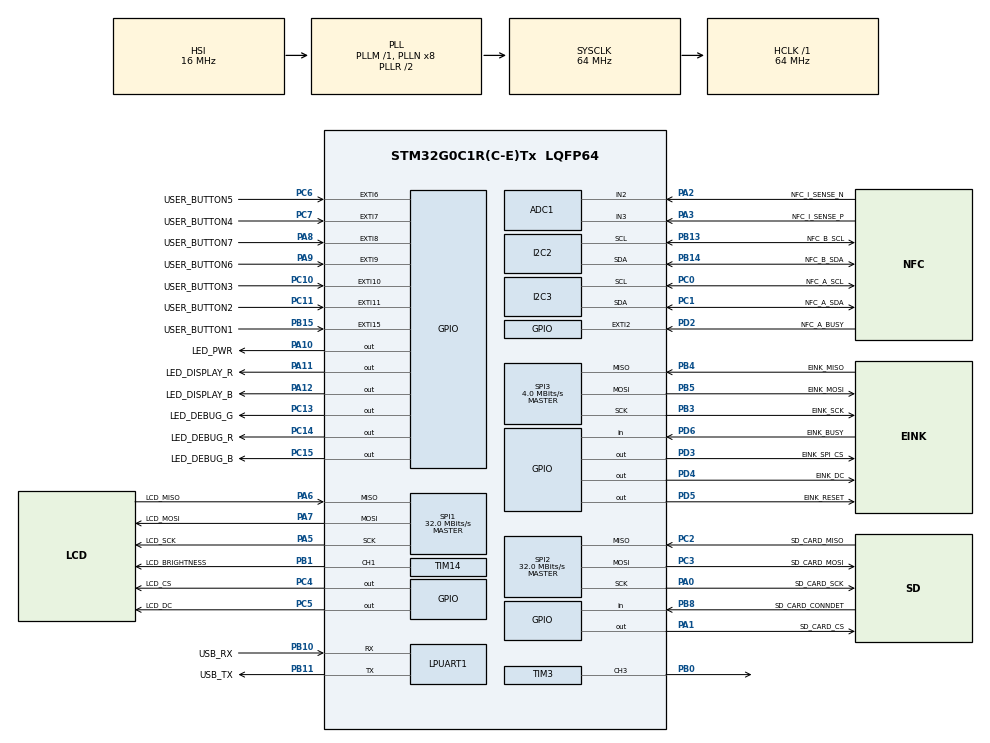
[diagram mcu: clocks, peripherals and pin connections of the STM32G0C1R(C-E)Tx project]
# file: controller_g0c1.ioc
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ADC1.Channel-0\#ChannelRegularConversion=ADC_CHANNEL_2
ADC1.NbrOfConversionFlag=1
ADC1.Rank-0\#ChannelRegularConversion=1
ADC1.SamplingTime-0\#ChannelRegularConversion=ADC_SAMPLINGTIME_COMMON_1
ADC1.SelectedChannel=ADC_CHANNEL_2|ADC_CHANNEL_3
ADC1.master=1
FREERTOS.Tasks01=defaultTask,24,128,StartDefaultTask,Default,NULL,Dynamic,NULL,NULL
FREERTOS.configUSE_NEWLIB_REENTRANT=1
I2C2.Timing=0x10B17DB5
I2C3.Speed=100
I2C3.Timing=0x10B17DB5
Mcu.Family=STM32G0
Mcu.Name=STM32G0C1R(C-E)Tx
Mcu.Package=LQFP64
NVIC.EXTI2_3_IRQn=true\:3\:0\:false\:false\:true\:true\:true\:true\:true
NVIC.EXTI4_15_IRQn=true\:3\:0\:false\:false\:true\:true\:true\:true\:true
NVIC.I2C2_3_IRQn=true\:3\:0\:false\:false\:true\:true\:true\:true\:true
NVIC.TIM1_BRK_UP_TRG_COM_IRQn=true\:3\:0\:false\:false\:true\:false\:false\:true\:true
NVIC.TimeBase=TIM1_BRK_UP_TRG_COM_IRQn
NVIC.TimeBaseIP=TIM1
PA0.GPIO_Label=SD_CARD_SCK
PA0.Mode=Full_Duplex_Master
PA0.Signal=SPI2_SCK
PA1.GPIO_Label=SD_CARD_CS
PA1.Signal=GPIO_Output
PA10.GPIO_Label=LED_PWR
PA10.Signal=GPIO_Output
PA11\ [PA9].GPIO_Label=LED_DISPLAY_R
PA11\ [PA9].Signal=GPIO_Output
PA12\ [PA10].GPIO_Label=LED_DISPLAY_B
PA12\ [PA10].Signal=GPIO_Output
PA2.GPIO_Label=NFC_I_SENSE_N
PA2.Mode=IN2
PA2.Signal=ADC1_IN2
PA3.GPIO_Label=NFC_I_SENSE_P
PA3.Mode=IN3
PA3.Signal=ADC1_IN3
PA5.GPIO_Label=LCD_SCK
PA5.Mode=Full_Duplex_Master
PA5.Signal=SPI1_SCK
PA6.GPIO_Label=LCD_MISO
PA6.Mode=Full_Duplex_Master
PA6.Signal=SPI1_MISO
PA7.GPIO_Label=LCD_MOSI
PA7.Mode=Full_Duplex_Master
PA7.Signal=SPI1_MOSI
PA8.GPIO_Label=USER_BUTTON7
PA8.GPIO_ModeDefaultEXTI=GPIO_MODE_IT_RISING_FALLING
PA8.Signal=GPXTI8
PA9.GPIO_Label=USER_BUTTON6
PA9.GPIO_ModeDefaultEXTI=GPIO_MODE_IT_RISING_FALLING
PA9.Signal=GPXTI9
PB0.Signal=S_TIM3_CH3
PB1.GPIO_Label=LCD_BRIGHTNESS
PB1.Signal=S_TIM14_CH1
PB10.GPIO_Label=USB_RX
PB10.Mode=Asynchronous
PB10.Signal=LPUART1_RX
PB11.GPIO_Label=USB_TX
PB11.Mode=Asynchronous
PB11.Signal=LPUART1_TX
PB13.GPIO_Label=NFC_B_SCL
PB13.Mode=I2C
PB13.Signal=I2C2_SCL
PB14.GPIO_Label=NFC_B_SDA
PB14.Mode=I2C
PB14.Signal=I2C2_SDA
PB15.GPIO_Label=USER_BUTTON1
PB15.GPIO_ModeDefaultEXTI=GPIO_MODE_IT_RISING_FALLING
PB15.Signal=GPXTI15
PB3.GPIO_Label=EINK_SCK
PB3.Mode=Full_Duplex_Master
PB3.Signal=SPI3_SCK
PB4.GPIO_Label=EINK_MISO
PB4.Mode=Full_Duplex_Master
PB4.Signal=SPI3_MISO
PB5.GPIO_Label=EINK_MOSI
PB5.Mode=Full_Duplex_Master
PB5.Signal=SPI3_MOSI
PB8.GPIO_Label=SD_CARD_CONNDET
PB8.Signal=GPIO_Input
PC0.GPIO_Label=NFC_A_SCL
PC0.Mode=I2C
PC0.Signal=I2C3_SCL
PC1.GPIO_Label=NFC_A_SDA
PC1.Mode=I2C
PC1.Signal=I2C3_SDA
PC10.GPIO_Label=USER_BUTTON3
PC10.GPIO_ModeDefaultEXTI=GPIO_MODE_IT_RISING_FALLING
PC10.Signal=GPXTI10
PC11.GPIO_Label=USER_BUTTON2
PC11.GPIO_ModeDefaultEXTI=GPIO_MODE_IT_RISING_FALLING
PC11.Signal=GPXTI11
PC13.GPIO_Label=LED_DEBUG_G
PC13.Signal=GPIO_Output
PC14-OSC32_IN\ (PC14).GPIO_Label=LED_DEBUG_R
PC14-OSC32_IN\ (PC14).Signal=GPIO_Output
PC15-OSC32_OUT\ (PC15).GPIO_Label=LED_DEBUG_B
PC15-OSC32_OUT\ (PC15).Signal=GPIO_Output
PC2.GPIO_Label=SD_CARD_MISO
PC2.Mode=Full_Duplex_Master
PC2.Signal=SPI2_MISO
PC3.GPIO_Label=SD_CARD_MOSI
PC3.Mode=Full_Duplex_Master
PC3.Signal=SPI2_MOSI
PC4.GPIO_Label=LCD_CS
PC4.Signal=GPIO_Output
PC5.GPIO_Label=LCD_DC
PC5.Signal=GPIO_Output
PC6.GPIO_Label=USER_BUTTON5
PC6.GPIO_ModeDefaultEXTI=GPIO_MODE_IT_RISING_FALLING
PC6.Signal=GPXTI6
PC7.GPIO_Label=USER_BUTTON4
PC7.GPIO_ModeDefaultEXTI=GPIO_MODE_IT_RISING_FALLING
PC7.Signal=GPXTI7
PD2.GPIO_Label=NFC_A_BUSY
PD2.Signal=GPXTI2
PD3.GPIO_Label=EINK_SPI_CS
PD3.Signal=GPIO_Output
PD4.GPIO_Label=EINK_DC
PD4.Signal=GPIO_Output
PD5.GPIO_Label=EINK_RESET
PD5.Signal=GPIO_Output
PD6.GPIO_Label=EINK_BUSY
PD6.Signal=GPIO_Input
ProjectManager.HeapSize=0x200
ProjectManager.StackSize=0x400
ProjectManager.TargetToolchain=STM32CubeIDE
RCC.ADCFreq_Value=64000000
RCC.AHBFreq_Value=64000000
RCC.CortexFreq_Value=64000000
RCC.EXTERNAL_CLOCK_VALUE=48000
RCC.HCLKFreq_Value=64000000
RCC.HSE_VALUE=8000000
RCC.HSI48_VALUE=48000000
RCC.HSI_VALUE=16000000
RCC.LSE_VALUE=32768
RCC.SYSCLKFreq_VALUE=64000000
RCC.SYSCLKSource=RCC_SYSCLKSOURCE_PLLCLK
RCC.USBFreq_Value=48000000
RCC.VCOOutputFreq_Value=128000000
SH.S_TIM14_CH1.0=TIM14_CH1,PWM Generation1 CH1
SH.S_TIM3_CH3.0=TIM3_CH3,PWM Generation3 CH3
SPI1.CalculateBaudRate=32.0 MBits/s
SPI1.Direction=SPI_DIRECTION_2LINES
SPI1.Mode=SPI_MODE_MASTER
SPI1.VirtualType=VM_MASTER
SPI2.CalculateBaudRate=32.0 MBits/s
SPI2.Direction=SPI_DIRECTION_2LINES
SPI2.Mode=SPI_MODE_MASTER
SPI2.VirtualType=VM_MASTER
SPI3.BaudRatePrescaler=SPI_BAUDRATEPRESCALER_16
SPI3.CalculateBaudRate=4.0 MBits/s
SPI3.Direction=SPI_DIRECTION_2LINES
SPI3.Mode=SPI_MODE_MASTER
SPI3.VirtualType=VM_MASTER
TIM14.Channel=TIM_CHANNEL_1
TIM3.Channel-PWM\ Generation3\ CH3=TIM_CHANNEL_3
VP_FREERTOS_VS_CMSIS_V2.Mode=CMSIS_V2
VP_RNG_VS_RNG.Mode=RNG_Activate
VP_SYS_VS_DBSignals.Mode=DisableDeadBatterySignals
VP_SYS_VS_tim1.Mode=TIM1
VP_TIM14_VS_ClockSourceINT.Mode=Enable_Timer
board=custom

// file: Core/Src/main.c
/* USER CODE BEGIN Header */
/**
  ******************************************************************************
  * @file           : main.c
  * @brief          : Main program body
  ******************************************************************************
  * @attention
  *
  * Copyright (c) 2025 STMicroelectronics.
  * All rights reserved.
  *
  * This software is licensed under terms that can be found in the LICENSE file
  * in the root directory of this software component.
  * If no LICENSE file comes with this software, it is provided AS-IS.
  *
  ******************************************************************************
  */
/* USER CODE END Header */
#include "main.h"
#include "cmsis_os.h"
#include "adc.h"
#include "i2c.h"
#include "usart.h"
#include "rng.h"
#include "spi.h"
#include "tim.h"
#include "gpio.h"

/* USER CODE BEGIN Includes */
#include "led.h"
/* USER CODE END Includes */

void SystemClock_Config(void);
void MX_FREERTOS_Init(void);

int main(void)
{

  /* MCU Configuration--------------------------------------------------------*/

  /* Reset of all peripherals, Initializes the Flash interface and the Systick. */
  HAL_Init();

  /* Configure the system clock */
  SystemClock_Config();

  /* Initialize all configured peripherals */
  MX_GPIO_Init();
  MX_ADC1_Init();
  MX_I2C2_Init();
  MX_I2C3_Init();
  MX_LPUART1_UART_Init();
  MX_SPI1_Init();
  MX_SPI2_Init();
  MX_SPI3_Init();
  MX_TIM3_Init();
  MX_TIM14_Init();
  MX_RNG_Init();

  /* Init scheduler */
  osKernelInitialize();

  /* Call init function for freertos objects (in cmsis_os2.c) */
  MX_FREERTOS_Init();

  /* Start scheduler */
  osKernelStart();

  /* We should never get here as control is now taken by the scheduler */

  /* Infinite loop */
  while (1)
  {

  }
}

void SystemClock_Config(void)
{
  RCC_OscInitTypeDef RCC_OscInitStruct = {0};
  RCC_ClkInitTypeDef RCC_ClkInitStruct = {0};

  /** Configure the main internal regulator output voltage
  */
  HAL_PWREx_ControlVoltageScaling(PWR_REGULATOR_VOLTAGE_SCALE1);

  /** Initializes the RCC Oscillators according to the specified parameters
  * in the RCC_OscInitTypeDef structure.
  */
  RCC_OscInitStruct.OscillatorType = RCC_OSCILLATORTYPE_HSI;
  RCC_OscInitStruct.HSIState = RCC_HSI_ON;
  RCC_OscInitStruct.HSIDiv = RCC_HSI_DIV1;
  RCC_OscInitStruct.HSICalibrationValue = RCC_HSICALIBRATION_DEFAULT;
  RCC_OscInitStruct.PLL.PLLState = RCC_PLL_ON;
  RCC_OscInitStruct.PLL.PLLSource = RCC_PLLSOURCE_HSI;
  RCC_OscInitStruct.PLL.PLLM = RCC_PLLM_DIV1;
  RCC_OscInitStruct.PLL.PLLN = 8;
  RCC_OscInitStruct.PLL.PLLP = RCC_PLLP_DIV2;
  RCC_OscInitStruct.PLL.PLLQ = RCC_PLLQ_DIV2;
  RCC_OscInitStruct.PLL.PLLR = RCC_PLLR_DIV2;
  if (HAL_RCC_OscConfig(&RCC_OscInitStruct) != HAL_OK)
  {
    Error_Handler();
  }

  /** Initializes the CPU, AHB and APB buses clocks
  */
  RCC_ClkInitStruct.ClockType = RCC_CLOCKTYPE_HCLK|RCC_CLOCKTYPE_SYSCLK
                              |RCC_CLOCKTYPE_PCLK1;
  RCC_ClkInitStruct.SYSCLKSource = RCC_SYSCLKSOURCE_PLLCLK;
  RCC_ClkInitStruct.AHBCLKDivider = RCC_SYSCLK_DIV1;
  RCC_ClkInitStruct.APB1CLKDivider = RCC_HCLK_DIV1;

  if (HAL_RCC_ClockConfig(&RCC_ClkInitStruct, FLASH_LATENCY_2) != HAL_OK)
  {
    Error_Handler();
  }
}

void HAL_TIM_PeriodElapsedCallback(TIM_HandleTypeDef *htim)
{
  if (htim->Instance == TIM1) {
    HAL_IncTick();
  }
}

void Error_Handler(void)
{
  /* USER CODE BEGIN Error_Handler_Debug */
  /* User can add his own implementation to report the HAL error return state */
  __disable_irq();
  while (1)
  {
    for(uint32_t x = 0; x < 64e6/50; x++);
    LED_enableSolid(LED_NFC_WORKING);
    for(uint32_t x = 0; x < 64e6/50; x++);
    LED_disable(LED_NFC_WORKING);
  }
  /* USER CODE END Error_Handler_Debug */
}
